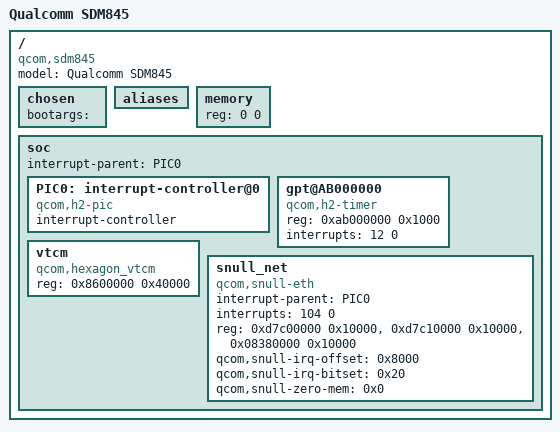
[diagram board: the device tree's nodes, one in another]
/dts-v1/;

/*  Bare minimum  */
/ {
	#address-cells = <1>;
	#size-cells = <1>;
	chosen { };
	aliases {
	};
	memory { device_type = "memory"; reg = <0 0>; };

};


/ {
	chosen {
		bootargs = "";
	};
};


/ {
        model = "Qualcomm SDM845";
        compatible = "qcom,sdm845";

	soc: soc {
		#address-cells = <1>;
		#size-cells = <1>;
		ranges;
		interrupt-parent = <&PIC0>;

		PIC0: interrupt-controller@0 {
			compatible = "qcom,h2-pic";
			interrupt-controller;
			#interrupt-cells = <2>;
		};

		gpt@AB000000 {
			compatible="qcom,h2-timer";
			reg = <0xab000000 0x1000>;
			interrupts = <12 0>;   /*  interrupts CPU directly; rising edge triggered */
		};
/*
		gpt@FE2A0000 {
			compatible="qcom,qtimer";
			reg = <0xfe2a0000 0x1000>;
			interrupts = <35>;
		};
*/

		/*
			Add 32 to l2vic interrupt
			[0] 18
			[1] 8
			[2] 33
			[3] 46
		 */
/*
		irqtest {
			compatible = "qcom,hexagon-irqtest";
			interrupt-parent = <&PIC0>;
			interrupts = <50 0>, <40 0>, <65 0>, <78 0>;
		};

		virtio_block@1e000 {
			compatible = "virtio,mmio";
			reg = <0x37c00000 0x100>;
			interrupts = <50 0>;
		};

*/

		/*  0x8400000 + 0x200000  */
		vtcm {
			compatible = "qcom,hexagon_vtcm";
			reg = <0x8600000 0x40000>;
		};

		snull_net {
			compatible = "qcom,snull-eth";
			interrupt-parent = <&PIC0>;
			interrupts = <104 0>;
			reg = <0xd7c00000 0x10000>,
			      <0xd7c10000 0x10000>,
			      <0x08380000 0x10000>;
			qcom,snull-irq-offset = <0x8000>;	/* TURING_QDSP6SS_IPC */
			qcom,snull-irq-bitset = <0x20>;	/* bit in this register to set */
			qcom,snull-zero-mem = <0x0>;
		};
	};
};



